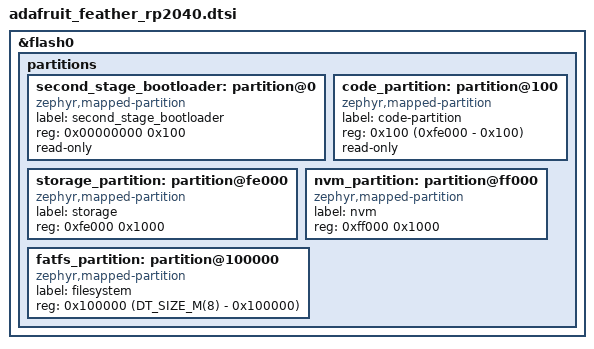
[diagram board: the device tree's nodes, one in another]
/* RP2040 UF2-native layout (no mcuboot): applied to the application image only.
 *
 * RP2040 boots from its own second-stage bootloader (UF2), so there is no
 * mcuboot domain. The fork still owns this layout so CircuitPython, Arduino,
 * and Wippersnapper share the same code/nvm/storage/filesystem placement.
 * Flash is 8 MB on the Adafruit Feather RP2040.
 */
&flash0 {
	/delete-node/ partitions;

	partitions {
		ranges;
		#address-cells = <1>;
		#size-cells = <1>;

		/* Reserved memory for the second stage bootloader */
		second_stage_bootloader: partition@0 {
			compatible = "zephyr,mapped-partition";
			label = "second_stage_bootloader";
			reg = <0x00000000 0x100>;
			read-only;
		};

		code_partition: partition@100 {
			compatible = "zephyr,mapped-partition";
			label = "code-partition";
			reg = <0x100 (0xfe000 - 0x100)>;
			read-only;
		};

		storage_partition: partition@fe000 {
			compatible = "zephyr,mapped-partition";
			label = "storage";
			reg = <0xfe000 0x1000>;
		};

		nvm_partition: partition@ff000 {
			compatible = "zephyr,mapped-partition";
			label = "nvm";
			reg = <0xff000 0x1000>;
		};

		fatfs_partition: partition@100000 {
			compatible = "zephyr,mapped-partition";
			label = "filesystem";
			reg = <0x100000 (DT_SIZE_M(8) - 0x100000)>;
		};
	};
};
